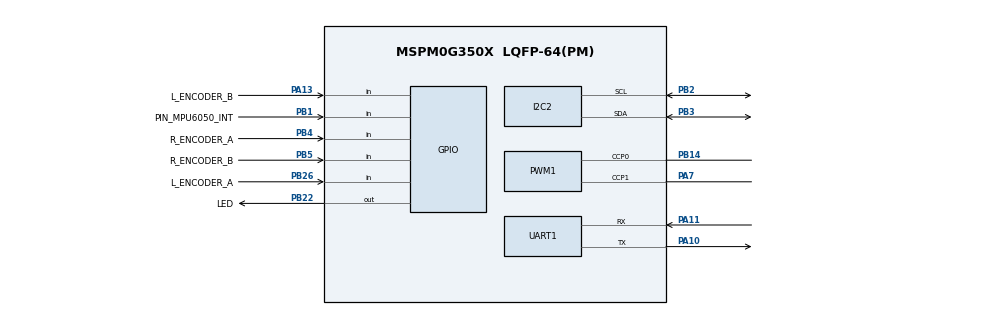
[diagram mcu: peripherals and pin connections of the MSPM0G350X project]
/**
 * @cliArgs --device "MSPM0G350X" --part "Default" --package "LQFP-64(PM)" --product "mspm0_sdk@2.05.01.00"
 * @versions {"tool":"1.24.0+4110"}
 */

/**
 * Import the modules used in this configuration.
 */
const GPIO   = scripting.addModule("/ti/driverlib/GPIO", {}, false);
const GPIO1  = GPIO.addInstance();
const GPIO2  = GPIO.addInstance();
const GPIO3  = GPIO.addInstance();
const GPIO4  = GPIO.addInstance();
const GPIO5  = GPIO.addInstance();
const I2C    = scripting.addModule("/ti/driverlib/I2C", {}, false);
const I2C1   = I2C.addInstance();
const I2C2   = I2C.addInstance();
const PWM    = scripting.addModule("/ti/driverlib/PWM", {}, false);
const PWM1   = PWM.addInstance();
const SYSCTL = scripting.addModule("/ti/driverlib/SYSCTL");
const UART   = scripting.addModule("/ti/driverlib/UART", {}, false);
const UART1  = UART.addInstance();

/**
 * Write custom configuration values to the imported modules.
 */
GPIO1.$name                         = "TEST_LED";
GPIO1.port                          = "PORTB";
GPIO1.associatedPins[0].$name       = "LED";
GPIO1.associatedPins[0].pin.$assign = "PB22";

const Board = scripting.addModule("/ti/driverlib/Board", {}, false);

GPIO2.$name                         = "GPIO_MPU6050";
GPIO2.associatedPins[0].direction   = "INPUT";
GPIO2.associatedPins[0].$name       = "PIN_MPU6050_INT";
GPIO2.associatedPins[0].pin.$assign = "PB1";

GPIO3.$name                          = "BIN";
GPIO3.associatedPins.create(2);
GPIO3.associatedPins[0].$name        = "BIN1";
GPIO3.associatedPins[0].assignedPin  = "6";
GPIO3.associatedPins[0].assignedPort = "PORTB";
GPIO3.associatedPins[1].$name        = "BIN2";
GPIO3.associatedPins[1].assignedPort = "PORTB";
GPIO3.associatedPins[1].assignedPin  = "7";

GPIO4.$name                          = "AIN";
GPIO4.associatedPins.create(2);
GPIO4.associatedPins[0].$name        = "AIN1";
GPIO4.associatedPins[0].assignedPort = "PORTB";
GPIO4.associatedPins[0].assignedPin  = "9";
GPIO4.associatedPins[1].$name        = "AIN2";
GPIO4.associatedPins[1].assignedPort = "PORTB";
GPIO4.associatedPins[1].assignedPin  = "10";

GPIO5.$name                               = "GPIO_ENCODER";
GPIO5.associatedPins.create(4);
GPIO5.associatedPins[0].$name             = "L_ENCODER_A";
GPIO5.associatedPins[0].direction         = "INPUT";
GPIO5.associatedPins[0].internalResistor  = "PULL_UP";
GPIO5.associatedPins[0].interruptEn       = true;
GPIO5.associatedPins[0].polarity          = "RISE_FALL";
GPIO5.associatedPins[0].interruptPriority = "1";
GPIO5.associatedPins[0].pin.$assign       = "PB26";
GPIO5.associatedPins[1].$name             = "L_ENCODER_B";
GPIO5.associatedPins[1].direction         = "INPUT";
GPIO5.associatedPins[1].internalResistor  = "PULL_UP";
GPIO5.associatedPins[1].interruptEn       = true;
GPIO5.associatedPins[1].polarity          = "RISE_FALL";
GPIO5.associatedPins[1].interruptPriority = "1";
GPIO5.associatedPins[1].pin.$assign       = "PA13";
GPIO5.associatedPins[2].$name             = "R_ENCODER_A";
GPIO5.associatedPins[2].internalResistor  = "PULL_UP";
GPIO5.associatedPins[2].direction         = "INPUT";
GPIO5.associatedPins[2].interruptEn       = true;
GPIO5.associatedPins[2].interruptPriority = "1";
GPIO5.associatedPins[2].polarity          = "RISE_FALL";
GPIO5.associatedPins[2].pin.$assign       = "PB4";
GPIO5.associatedPins[3].$name             = "R_ENCODER_B";
GPIO5.associatedPins[3].direction         = "INPUT";
GPIO5.associatedPins[3].internalResistor  = "PULL_UP";
GPIO5.associatedPins[3].interruptEn       = true;
GPIO5.associatedPins[3].polarity          = "RISE_FALL";
GPIO5.associatedPins[3].interruptPriority = "1";
GPIO5.associatedPins[3].pin.$assign       = "PB5";

I2C1.basicEnableController             = true;
I2C1.basicControllerBusSpeed           = 400000;
I2C1.$name                             = "I2C_OLED";
I2C1.peripheral.$assign                = "I2C0";
I2C1.sdaPinConfig.$name                = "ti_driverlib_gpio_GPIOPinGeneric0";
I2C1.sdaPinConfig.hideOutputInversion  = scripting.forceWrite(false);
I2C1.sdaPinConfig.onlyInternalResistor = scripting.forceWrite(false);
I2C1.sdaPinConfig.passedPeripheralType = scripting.forceWrite("Digital");
I2C1.sclPinConfig.$name                = "ti_driverlib_gpio_GPIOPinGeneric1";
I2C1.sclPinConfig.hideOutputInversion  = scripting.forceWrite(false);
I2C1.sclPinConfig.onlyInternalResistor = scripting.forceWrite(false);
I2C1.sclPinConfig.passedPeripheralType = scripting.forceWrite("Digital");

I2C2.$name                             = "I2C_MPU6050";
I2C2.basicEnableController             = true;
I2C2.basicControllerBusSpeed           = 400000;
I2C2.peripheral.$assign                = "I2C1";
I2C2.peripheral.sdaPin.$assign         = "PB3";
I2C2.peripheral.sclPin.$assign         = "PB2";
I2C2.sdaPinConfig.$name                = "ti_driverlib_gpio_GPIOPinGeneric2";
I2C2.sdaPinConfig.hideOutputInversion  = scripting.forceWrite(false);
I2C2.sdaPinConfig.onlyInternalResistor = scripting.forceWrite(false);
I2C2.sdaPinConfig.passedPeripheralType = scripting.forceWrite("Digital");
I2C2.sclPinConfig.$name                = "ti_driverlib_gpio_GPIOPinGeneric3";
I2C2.sclPinConfig.hideOutputInversion  = scripting.forceWrite(false);
I2C2.sclPinConfig.onlyInternalResistor = scripting.forceWrite(false);
I2C2.sclPinConfig.passedPeripheralType = scripting.forceWrite("Digital");

PWM1.$name                      = "PWM_0";
PWM1.clockPrescale              = 32;
PWM1.timerCount                 = 100;
PWM1.peripheral.ccp0Pin.$assign = "PB14";
PWM1.peripheral.ccp1Pin.$assign = "PA7";
PWM1.PWM_CHANNEL_0.$name        = "ti_driverlib_pwm_PWMTimerCC0";
PWM1.PWM_CHANNEL_0.dutyCycle    = 50;
PWM1.PWM_CHANNEL_1.$name        = "ti_driverlib_pwm_PWMTimerCC1";
PWM1.PWM_CHANNEL_1.dutyCycle    = 70;
PWM1.ccp0PinConfig.$name        = "ti_driverlib_gpio_GPIOPinGeneric4";
PWM1.ccp1PinConfig.$name        = "ti_driverlib_gpio_GPIOPinGeneric5";

SYSCTL.forceDefaultClkConfig = true;

UART1.$name                    = "UART_0";
UART1.enabledInterrupts        = ["RX"];
UART1.peripheral.$assign       = "UART0";
UART1.peripheral.rxPin.$assign = "PA11";
UART1.peripheral.txPin.$assign = "PA10";
UART1.txPinConfig.$name        = "ti_driverlib_gpio_GPIOPinGeneric6";
UART1.rxPinConfig.$name        = "ti_driverlib_gpio_GPIOPinGeneric7";

/**
 * Pinmux solution for unlocked pins/peripherals. This ensures that minor changes to the automatic solver in a future
 * version of the tool will not impact the pinmux you originally saw.  These lines can be completely deleted in order to
 * re-solve from scratch.
 */
Board.peripheral.$suggestSolution            = "DEBUGSS";
Board.peripheral.swclkPin.$suggestSolution   = "PA20";
Board.peripheral.swdioPin.$suggestSolution   = "PA19";
GPIO3.associatedPins[0].pin.$suggestSolution = "PB6";
GPIO3.associatedPins[1].pin.$suggestSolution = "PB7";
GPIO4.associatedPins[0].pin.$suggestSolution = "PB9";
GPIO4.associatedPins[1].pin.$suggestSolution = "PB10";
I2C1.peripheral.sdaPin.$suggestSolution      = "PA0";
I2C1.peripheral.sclPin.$suggestSolution      = "PA1";
PWM1.peripheral.$suggestSolution             = "TIMA0";
SYSCTL.peripheral.$suggestSolution           = "SYSCTL";
